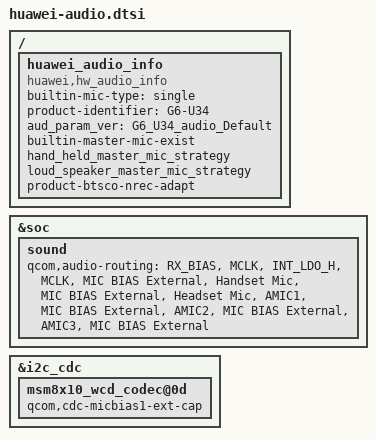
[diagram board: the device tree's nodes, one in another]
/ {
        huawei_audio_info {
                  compatible = "huawei,hw_audio_info";
                  builtin-mic-type = "single";
                  product-identifier = "G6-U34";
                  status = "ok";
                  aud_param_ver = "G6_U34_audio_Default";
                  builtin-master-mic-exist;
                  hand_held_master_mic_strategy;
                  loud_speaker_master_mic_strategy;
                  product-btsco-nrec-adapt;
        };
};
&soc {
    sound {
        qcom,audio-routing =
            "RX_BIAS", "MCLK",
            "INT_LDO_H", "MCLK",
            "MIC BIAS External", "Handset Mic",
            "MIC BIAS External", "Headset Mic",
            "AMIC1", "MIC BIAS External",
            "AMIC2", "MIC BIAS External",
            "AMIC3", "MIC BIAS External";
	};
};
&i2c_cdc {
        msm8x10_wcd_codec@0d{	
            qcom,cdc-micbias1-ext-cap;				
          };
};
